# STM32F030xC register map
File version: 1.0
Registers are 32-bit, read-write, reset 0x0 unless marked. A register's access mark holds for its fields unless they carry their own. Offsets are from the block's base; [hi:lo] are bit positions; {n}, {i} and the like mark numbered series; 'fields as' and 'values as' point back to an identical list.

## DMA1
Base 0x40020000
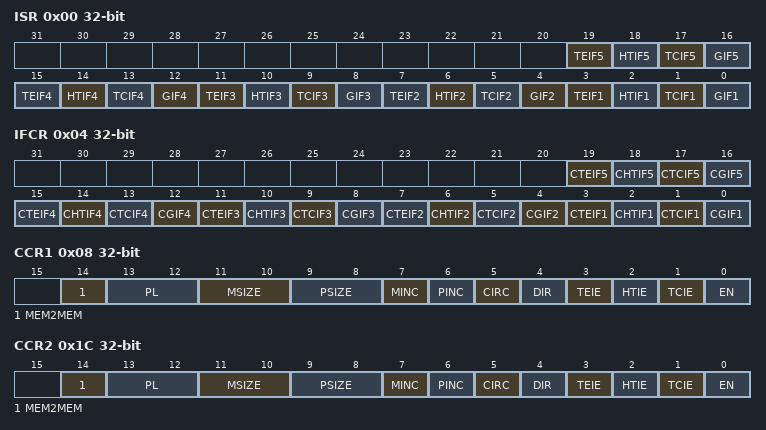
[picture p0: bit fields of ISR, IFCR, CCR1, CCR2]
0x00 ISR — DMA interrupt status register
  [4n-1] TEIF{n} (n=1..5) — Channel {n} Transfer Error flag
  [4n-2] HTIF{n} (n=1..5) — Channel {n} Half Transfer flag
  [4n-3] TCIF{n} (n=1..5) — Channel {n} Transfer Complete flag
  [4n-4] GIF{n} (n=1..5) — Channel {n} Global interrupt flag
0x04 IFCR — DMA interrupt flag clear register
  [4n-1] CTEIF{n} (n=1..5) — Channel {n} Transfer Error clear
  [4n-2] CHTIF{n} (n=1..5) — Channel {n} Half Transfer clear
  [4n-3] CTCIF{n} (n=1..5) — Channel {n} Transfer Complete clear
  [4n-4] CGIF{n} (n=1..5) — Channel {n} Global interrupt clear
0x08 CCR1 — DMA channel x configuration register
  [14] MEM2MEM — Memory to memory mode
  [13:12] PL — PL[1:0] bits(Channel Priority level)
  [11:10] MSIZE — MSIZE[1:0] bits (Memory size)
  [9:8] PSIZE — PSIZE[1:0] bits (Peripheral size)
  [7] MINC — Memory increment mode
  [6] PINC — Peripheral increment mode
  [5] CIRC — Circular mode
  [4] DIR — Data transfer direction
  [3] TEIE — Transfer error interrupt enable
  [2] HTIE — Half Transfer interrupt enable
  [1] TCIE — Transfer complete interrupt enable
  [0] EN — Channel enable
0x0C CNDTR1 — DMA channel x number of data register
  [15:0] NDT — Number of data to Transfer
0x10 CPAR1 — DMA channel x peripheral address register
  [31:0] PA — Peripheral Address
{0x0+0x14*i} CMAR{i} (i=1..5) — DMA channel x memory address register
  [31:0] MA — Memory Address
0x1C CCR2 — DMA channel x configuration register
  fields as CCR1
0x20 CNDTR2 — DMA channel x number of data register
  [15:0] NDT — Number of data to Transfer
0x24 CPAR2 — DMA channel x peripheral address register
  [31:0] PA — Peripheral Address
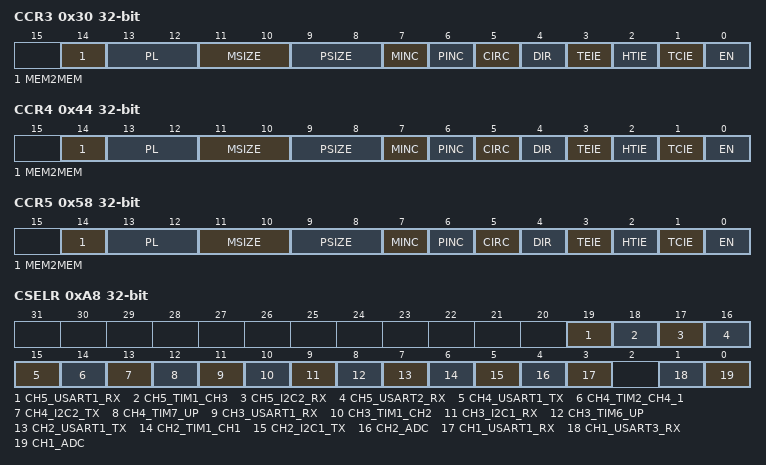
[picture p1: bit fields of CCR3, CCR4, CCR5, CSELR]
0x30 CCR3 — DMA channel x configuration register
  fields as CCR1
0x34 CNDTR3 — DMA channel x number of data register
  [15:0] NDT — Number of data to Transfer
0x38 CPAR3 — DMA channel x peripheral address register
  [31:0] PA — Peripheral Address
0x44 CCR4 — DMA channel x configuration register
  fields as CCR1
0x48 CNDTR4 — DMA channel x number of data register
  [15:0] NDT — Number of data to Transfer
0x4C CPAR4 — DMA channel x peripheral address register
  [31:0] PA — Peripheral Address
0x58 CCR5 — DMA channel x configuration register
  fields as CCR1
0x5C CNDTR5 — DMA channel x number of data register
  [15:0] NDT — Number of data to Transfer
0x60 CPAR5 — DMA channel x peripheral address register
  [31:0] PA — Peripheral Address
0xA8 CSELR — Channel selection register
  [19] CH5_USART1_RX — Remap USART1 Rx on DMA1 channel 5
  [18] CH5_TIM1_CH3 — Remap TIM1 channel 3 on DMA1 channel 5
  [17] CH5_I2C2_RX — Remap I2C2 Rx on DMA1 channel 5
  [16] CH5_USART2_RX — Remap USART2 Rx on DMA1 channel 5
  [15] CH4_USART1_TX — Remap USART1 Tx on DMA1 channel 4
  [14] CH4_TIM2_CH4_1 — Remap TIM2 channel 4 on DMA1 channel 4
  [13] CH4_I2C2_TX — Remap I2C2 Tx on DMA1 channel 4
  [12] CH4_TIM7_UP — Remap TIM7 up on DMA1 channel 4
  [11] CH3_USART1_RX — Remap USART1 Rx on DMA1 channel 3
  [10] CH3_TIM1_CH2 — Remap TIM1 channel 2 on DMA1 channel 3
  [9] CH3_I2C1_RX — Remap I2C1 Rx on DMA1 channel 3
  [8] CH3_TIM6_UP — Remap TIM6 up on DMA1 channel 3
  [7] CH2_USART1_TX — Remap USART1 Tx on DMA1 channel 2
  [6] CH2_TIM1_CH1 — Remap TIM1 channel 1 on DMA1 channel 2
  [5] CH2_I2C1_TX — Remap I2C1 Tx on DMA1 channel 2
  [4] CH2_ADC — Remap ADC on DMA1 channel 2
  [3] CH1_USART1_RX — Remap USART1 Rx on DMA1 channel 1
  [1] CH1_USART3_RX — Remap USART3 Rx on DMA1 channel 1
  [0] CH1_ADC — Remap ADC on DMA1 Channel 1
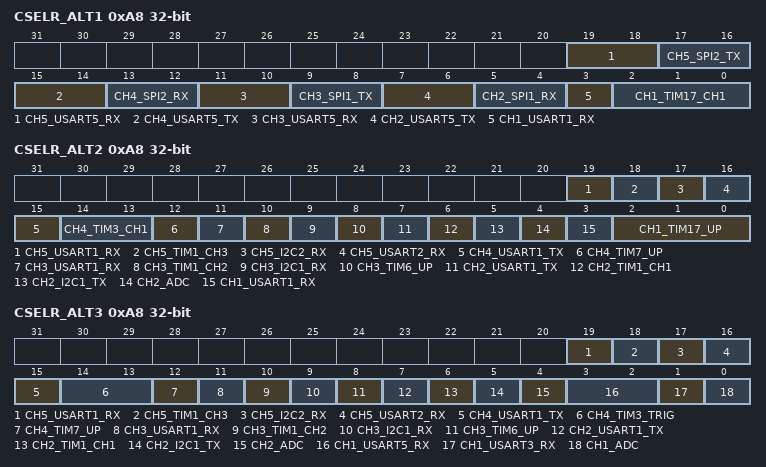
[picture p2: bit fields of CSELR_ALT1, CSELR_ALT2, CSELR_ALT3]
0xA8 CSELR_ALT1 (alternate view of CSELR) — Channel selection register
  [19:18] CH5_USART5_RX — Remap USART5 Rx on DMA1 channel 5
  [17:16] CH5_SPI2_TX — Remap SPI1 Tx on DMA1 channel 5
  [15:14] CH4_USART5_TX — Remap USART5 Tx on DMA1 channel 4
  [13:12] CH4_SPI2_RX — Remap SPI2 Rx on DMA1 channel 4
  [11:10] CH3_USART5_RX — Remap USART5 Rx on DMA1 channel 3
  [9:8] CH3_SPI1_TX — Remap SPI1 Tx on DMA1 channel 3
  [7:6] CH2_USART5_TX — Remap USART5 Tx on DMA1 channel 2
  [5:4] CH2_SPI1_RX — Remap SPI1 Rx on DMA1 channel 2
  [3] CH1_USART1_RX — Remap USART1 Rx on DMA1 channel 1
  [2:0] CH1_TIM17_CH1 — Remap TIM17 channel 1 on DMA1 channel 1
0xA8 CSELR_ALT2 (alternate view of CSELR) — Channel selection register
  [19] CH5_USART1_RX — Remap USART1 Rx on DMA1 channel 5
  [18] CH5_TIM1_CH3 — Remap TIM1 channel 3 on DMA1 channel 5
  [17] CH5_I2C2_RX — Remap I2C2 Rx on DMA1 channel 5
  [16] CH5_USART2_RX — Remap USART2 Rx on DMA1 channel 5
  [15] CH4_USART1_TX — Remap USART1 Tx on DMA1 channel 4
  [14:13] CH4_TIM3_CH1 — Remap TIM3 channel 1 on DMA1 channel 4
  [12] CH4_TIM7_UP — Remap TIM7 up on DMA1 channel 4
  [11] CH3_USART1_RX — Remap USART1 Rx on DMA1 channel 3
  [10] CH3_TIM1_CH2 — Remap TIM1 channel 2 on DMA1 channel 3
  [9] CH3_I2C1_RX — Remap I2C1 Rx on DMA1 channel 3
  [8] CH3_TIM6_UP — Remap TIM6 up on DMA1 channel 3
  [7] CH2_USART1_TX — Remap USART1 Tx on DMA1 channel 2
  [6] CH2_TIM1_CH1 — Remap TIM1 channel 1 on DMA1 channel 2
  [5] CH2_I2C1_TX — Remap I2C1 Tx on DMA1 channel 2
  [4] CH2_ADC — Remap ADC on DMA1 channel 2
  [3] CH1_USART1_RX — Remap USART1 Rx on DMA1 channel 1
  [2:0] CH1_TIM17_UP — Remap TIM17 up on DMA1 channel 1
0xA8 CSELR_ALT3 (alternate view of CSELR) — Channel selection register
  [19] CH5_USART1_RX — Remap USART1 Rx on DMA1 channel 5
  [18] CH5_TIM1_CH3 — Remap TIM1 channel 3 on DMA1 channel 5
  [17] CH5_I2C2_RX — Remap I2C2 Rx on DMA1 channel 5
  [16] CH5_USART2_RX — Remap USART2 Rx on DMA1 channel 5
  [15] CH4_USART1_TX — Remap USART1 Tx on DMA1 channel 4
  [14:13] CH4_TIM3_TRIG — Remap TIM3 Trig on DMA1 channel 4
  [12] CH4_TIM7_UP — Remap TIM7 up on DMA1 channel 4
  [11] CH3_USART1_RX — Remap USART1 Rx on DMA1 channel 3
  [10] CH3_TIM1_CH2 — Remap TIM1 channel 2 on DMA1 channel 3
  [9] CH3_I2C1_RX — Remap I2C1 Rx on DMA1 channel 3
  [8] CH3_TIM6_UP — Remap TIM6 up on DMA1 channel 3
  [7] CH2_USART1_TX — Remap USART1 Tx on DMA1 channel 2
  [6] CH2_TIM1_CH1 — Remap TIM1 channel 1 on DMA1 channel 2
  [5] CH2_I2C1_TX — Remap I2C1 Tx on DMA1 channel 2
  [4] CH2_ADC — Remap ADC on DMA1 channel 2
  [3:2] CH1_USART5_RX — Remap USART5 Rx on DMA1 channel 1
  [1] CH1_USART3_RX — Remap USART3 Rx on DMA1 channel 1
  [0] CH1_ADC — Remap ADC on DMA1 Channel 1
